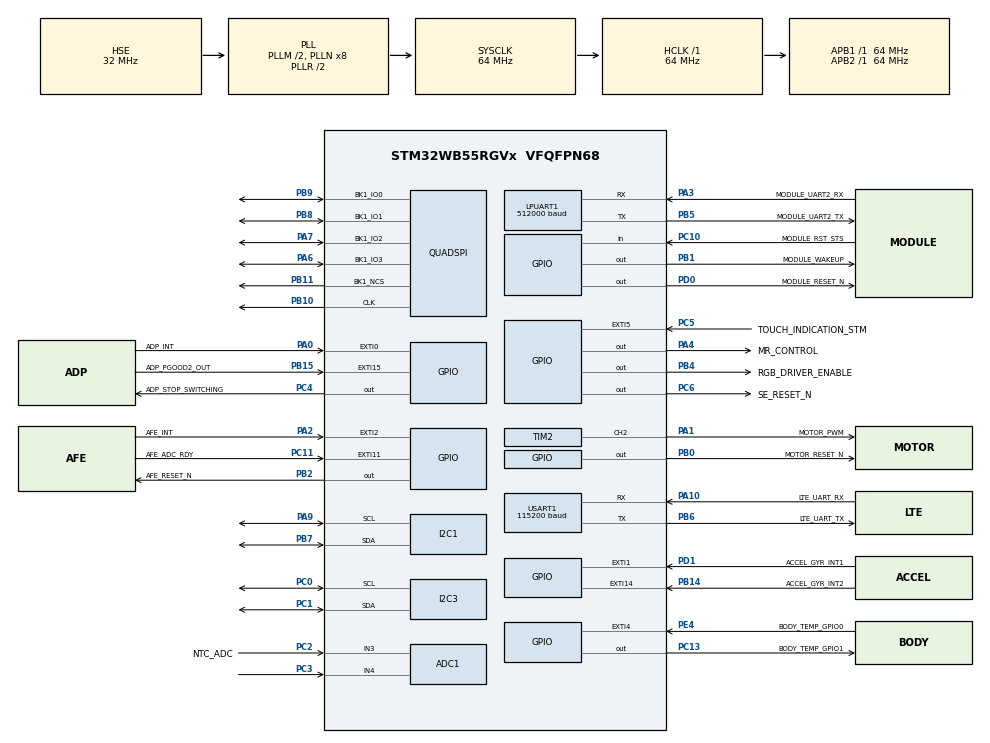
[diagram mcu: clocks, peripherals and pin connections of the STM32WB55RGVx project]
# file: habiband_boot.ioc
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ADC1.Channel-0\#ChannelRegularConversion=ADC_CHANNEL_3
ADC1.NbrOfConversionFlag=1
ADC1.OffsetNumber-0\#ChannelRegularConversion=ADC_OFFSET_NONE
ADC1.Rank-0\#ChannelRegularConversion=1
ADC1.SamplingTime-0\#ChannelRegularConversion=ADC_SAMPLETIME_2CYCLES_5
ADC1.master=1
I2C1.Timing=0x10707DBC
I2C3.Timing=0x10707DBC
LPUART1.BaudRate=512000
LPUART1.DMADisableonRxErrorParam=UART_ADVFEATURE_DMA_DISABLEONRXERROR
LPUART1.OverrunDisableParam=UART_ADVFEATURE_OVERRUN_DISABLE
Mcu.Family=STM32WB
Mcu.Name=STM32WB55RGVx
Mcu.Package=VFQFPN68
NVIC.EXTI15_10_IRQn=true\:0\:0\:false\:false\:true\:true\:true\:true
NVIC.EXTI1_IRQn=true\:0\:0\:false\:false\:true\:true\:true\:true
NVIC.EXTI4_IRQn=true\:0\:0\:false\:false\:true\:true\:true\:true
NVIC.EXTI9_5_IRQn=true\:0\:0\:false\:false\:true\:true\:true\:true
NVIC.HSEM_IRQn=true\:0\:0\:false\:false\:true\:false\:true\:true
NVIC.IPCC_C1_RX_IRQn=true\:0\:0\:false\:false\:true\:true\:true\:true
NVIC.IPCC_C1_TX_IRQn=true\:0\:0\:false\:false\:true\:true\:true\:true
NVIC.PriorityGroup=NVIC_PRIORITYGROUP_4
NVIC.RCC_IRQn=true\:0\:0\:false\:false\:true\:true\:false\:true
NVIC.RTC_WKUP_IRQn=true\:0\:0\:false\:false\:true\:true\:true\:true
NVIC.WWDG_IRQn=true\:0\:0\:false\:false\:true\:true\:true\:true
OSC_IN.Mode=HSE-External-Oscillator
OSC_IN.Signal=RCC_OSC_IN
OSC_OUT.Mode=HSE-External-Oscillator
OSC_OUT.Signal=RCC_OSC_OUT
PA0.GPIO_Label=ADP_INT
PA0.GPIO_ModeDefaultEXTI=GPIO_MODE_IT_FALLING
PA0.GPIO_PuPd=GPIO_PULLUP
PA0.Signal=GPXTI0
PA1.GPIO_Label=MOTOR_PWM
PA1.Signal=S_TIM2_CH2
PA10.GPIO_Label=LTE_UART_RX
PA10.Mode=Asynchronous
PA10.Signal=USART1_RX
PA11.GPIO_Label=LTE_UART_CTS
PA11.Signal=USART1_CTS
PA12.GPIO_Label=LTE_UART_RTS
PA12.Signal=USART1_RTS
PA13.Mode=Serial_Wire
PA13.Signal=SYS_JTMS-SWDIO
PA14.Mode=Serial_Wire
PA14.Signal=SYS_JTCK-SWCLK
PA15.Signal=SYS_JTDI
PA2.GPIO_Label=AFE_INT
PA2.Signal=GPXTI2
PA3.GPIO_Label=MODULE_UART2_RX
PA3.GPIO_Speed=GPIO_SPEED_FREQ_LOW
PA3.Mode=Asynchronous
PA3.Signal=LPUART1_RX
PA4.GPIO_Label=MR_CONTROL
PA4.GPIO_PuPd=GPIO_NOPULL
PA4.Signal=GPIO_Output
PA6.Mode=Single Bank 1
PA6.Signal=QUADSPI_BK1_IO3
PA7.Mode=Single Bank 1
PA7.Signal=QUADSPI_BK1_IO2
PA9.GPIO_Pu=GPIO_PULLUP
PA9.Mode=I2C
PA9.Signal=I2C1_SCL
PB0.GPIO_Label=MOTOR_RESET_N
PB0.Signal=GPIO_Output
PB1.GPIO_Label=MODULE_WAKEUP
PB1.Signal=GPIO_Output
PB10.Mode=Single Bank 1
PB10.Signal=QUADSPI_CLK
PB11.Mode=Single Bank 1
PB11.Signal=QUADSPI_BK1_NCS
PB12.GPIO_Label=MODULE_UART2_RTS
PB12.Signal=LPUART1_RTS
PB13.GPIO_Label=MODULE_UART2_CTS
PB13.Signal=LPUART1_CTS
PB14.GPIO_Label=ACCEL_GYR_INT2
PB14.Signal=GPXTI14
PB15.GPIO_Label=ADP_PGOOD2_OUT
PB15.Signal=GPXTI15
PB2.GPIO_Label=AFE_RESET_N
PB2.Signal=GPIO_Output
PB3.Signal=SYS_JTDO-SWO
PB4.GPIO_Label=RGB_DRIVER_ENABLE
PB4.GPIO_PuPd=GPIO_NOPULL
PB4.Signal=GPIO_Output
PB5.GPIO_Label=MODULE_UART2_TX
PB5.GPIO_Speed=GPIO_SPEED_FREQ_LOW
PB5.Mode=Asynchronous
PB5.Signal=LPUART1_TX
PB6.GPIO_Label=LTE_UART_TX
PB6.Mode=Asynchronous
PB6.Signal=USART1_TX
PB7.GPIO_Pu=GPIO_PULLUP
PB7.Mode=I2C
PB7.Signal=I2C1_SDA
PB8.Mode=Single Bank 1
PB8.Signal=QUADSPI_BK1_IO1
PB9.Mode=Single Bank 1
PB9.Signal=QUADSPI_BK1_IO0
PC0.GPIO_Pu=GPIO_PULLUP
PC0.Mode=I2C
PC0.Signal=I2C3_SCL
PC1.GPIO_Pu=GPIO_PULLUP
PC1.Mode=I2C
PC1.Signal=I2C3_SDA
PC10.GPIO_Label=MODULE_RST_STS
PC10.Signal=GPIO_Input
PC11.GPIO_Label=AFE_ADC_RDY
PC11.Signal=GPXTI11
PC12.GPIO_Label=STM_WAKEUP
PC12.Mode=SYS_WakeUp2
PC12.Signal=SYS_WKUP3
PC13.GPIO_Label=BODY_TEMP_GPIO1
PC13.Signal=GPIO_Output
PC14-OSC32_IN.Mode=LSE-External-Oscillator
PC14-OSC32_IN.Signal=RCC_OSC32_IN
PC15-OSC32_OUT.Mode=LSE-External-Oscillator
PC15-OSC32_OUT.Signal=RCC_OSC32_OUT
PC2.GPIO_Label=NTC_ADC
PC2.Signal=ADCx_IN3
PC3.Signal=ADCx_IN4
PC4.GPIO_Label=ADP_STOP_SWITCHING
PC4.Signal=GPIO_Output
PC5.GPIO_Label=TOUCH_INDICATION_STM
PC5.Signal=GPXTI5
PC6.GPIO_Label=SE_RESET_N
PC6.GPIO_PuPd=GPIO_NOPULL
PC6.Signal=GPIO_Output
PD0.GPIO_Label=MODULE_RESET_N
PD0.Signal=GPIO_Output
PD1.GPIO_Label=ACCEL_GYR_INT1
PD1.GPIO_ModeDefaultEXTI=GPIO_MODE_IT_RISING
PD1.GPIO_PuPd=GPIO_PULLDOWN
PD1.Signal=GPXTI1
PE4.GPIO_Label=BODY_TEMP_GPIO0
PE4.GPIO_ModeDefaultEXTI=GPIO_MODE_IT_RISING_FALLING
PE4.Signal=GPXTI4
ProjectManager.HeapSize=0x400
ProjectManager.StackSize=0x800
ProjectManager.TargetToolchain=STM32CubeIDE
RCC.ADCFreq_Value=48000000
RCC.AHB2CLKDivider=RCC_SYSCLK_DIV2
RCC.AHBFreq_Value=64000000
RCC.APB1Freq_Value=64000000
RCC.APB1TimFreq_Value=64000000
RCC.APB2Freq_Value=64000000
RCC.APB2TimFreq_Value=64000000
RCC.APB3Freq_Value=16000000
RCC.Cortex2_Div=SYSTICK_CLKSOURCE_HCLK_DIV8
RCC.CortexFreq_Value=64000000
RCC.HCLKFreq_Value=64000000
RCC.HSE_VALUE=32000000
RCC.HSI48_VALUE=48000000
RCC.HSI_VALUE=16000000
RCC.PLLM=RCC_PLLM_DIV2
RCC.PLLSAI1N=6
RCC.PLLSourceVirtual=RCC_PLLSOURCE_HSE
RCC.RFWKPClockSelection=RCC_RFWKPCLKSOURCE_LSE
RCC.RTCClockSelection=RCC_RTCCLKSOURCE_LSE
RCC.SYSCLKFreq_VALUE=64000000
RCC.SYSCLKSource=RCC_SYSCLKSOURCE_PLLCLK
RCC.USBFreq_Value=48000000
RCC.VCOOutputFreq_Value=128000000
RF1.Mode=RF1_Activate
RF1.Signal=RF_RF1
SH.ADCx_IN3.0=ADC1_IN3,IN3-Single-Ended
SH.ADCx_IN4.0=ADC1_IN4,IN4-Single-Ended
SH.S_TIM2_CH2.0=TIM2_CH2,PWM Generation2 CH2
STM32_WPAN.BT_SIG_BLOOD_PRESSURE_SENSOR=Disabled
STM32_WPAN.BT_SIG_HEALTH_THERMOMETER_SENSOR=Disabled
STM32_WPAN.BT_SIG_HEART_RATE_SENSOR=Disabled
STM32_WPAN.CFG_BLE_ATT_VALUE_ARRAY_SIZE=4096
STM32_WPAN.CFG_BLE_MAX_ATT_MTU=256
STM32_WPAN.CFG_BLE_NUM_GATT_SERVICES=10
STM32_WPAN.CFG_BLE_NUM_LINK=1
STM32_WPAN.CFG_GAP_DEVICE_NAME=habiband
STM32_WPAN.CUSTOM_P2P_SERVER=Disabled
STM32_WPAN.CUSTOM_TEMPLATE=Enabled
STM32_WPAN.INCLUDE_AD_TYPE_TX_POWER_LEVEL=1
STM32_WPAN.NUMBER_OF_SERVICES=1
STM32_WPAN.PAIRING_PARAMETERS=ON
STM32_WPAN.SERVICE1_CHAR1_LENGTH_CHARACTERISTIC=CHAR_VALUE_LEN_VARIABLE
STM32_WPAN.SERVICE1_CHAR1_LONG_NAME=BOOTLOADER_PORT_RX
STM32_WPAN.SERVICE1_CHAR1_PROP_WRITE=CHAR_PROP_WRITE
STM32_WPAN.SERVICE1_CHAR1_SHORT_NAME=BOOTLOADER_PORT_RX
STM32_WPAN.SERVICE1_CHAR1_UUID=B0 01
STM32_WPAN.SERVICE1_CHAR1_VALUE_LENGTH=200
STM32_WPAN.SERVICE1_CHAR2_LENGTH_CHARACTERISTIC=CHAR_VALUE_LEN_VARIABLE
STM32_WPAN.SERVICE1_CHAR2_LONG_NAME=BOOTLOADER_PORT_TX
STM32_WPAN.SERVICE1_CHAR2_PROP_NOTIFY=CHAR_PROP_NOTIFY
STM32_WPAN.SERVICE1_CHAR2_PROP_READ=CHAR_PROP_READ
STM32_WPAN.SERVICE1_CHAR2_SHORT_NAME=BOOTLOADER_PORT_TX
STM32_WPAN.SERVICE1_CHAR2_UUID=B0 02
STM32_WPAN.SERVICE1_CHAR2_VALUE_LENGTH=200
STM32_WPAN.SERVICE1_CHAR3_LENGTH_CHARACTERISTIC=CHAR_VALUE_LEN_VARIABLE
STM32_WPAN.SERVICE1_CHAR3_LONG_NAME=BOOTLOADER_STATUS
STM32_WPAN.SERVICE1_CHAR3_PROP_NOTIFY=CHAR_PROP_NOTIFY
STM32_WPAN.SERVICE1_CHAR3_PROP_READ=CHAR_PROP_READ
STM32_WPAN.SERVICE1_CHAR3_SHORT_NAME=BOOTLOADER_STATUS
STM32_WPAN.SERVICE1_CHAR3_UUID=B0 03
STM32_WPAN.SERVICE1_CHAR3_VALUE_LENGTH=20
STM32_WPAN.SERVICE1_CHAR4_LONG_NAME=BOOTLOADER_VERSION
STM32_WPAN.SERVICE1_CHAR4_PROP_READ=CHAR_PROP_READ
STM32_WPAN.SERVICE1_CHAR4_SHORT_NAME=BOOTLOADER_VERSION
STM32_WPAN.SERVICE1_CHAR4_UUID=B0 04
STM32_WPAN.SERVICE1_CHAR4_VALUE_LENGTH=20
STM32_WPAN.SERVICE1_LONG_NAME=SYSTEM_SERVICE
STM32_WPAN.SERVICE1_NUMBER_OF_CHARACTERISTICS=4
STM32_WPAN.SERVICE1_SHORT_NAME=SYSTEM_SERVICE
STM32_WPAN.SERVICE1_UUID=B0 00
STM32_WPAN.SERVICE2_CHAR1_LENGTH_CHARACTERISTIC=CHAR_VALUE_LEN_VARIABLE
STM32_WPAN.SERVICE2_CHAR1_LONG_NAME=ACCELEROMETER_POINTS
STM32_WPAN.SERVICE2_CHAR1_PROP_NOTIFY=CHAR_PROP_NOTIFY
STM32_WPAN.SERVICE2_CHAR1_PROP_READ=CHAR_PROP_READ
STM32_WPAN.SERVICE2_CHAR1_SHORT_NAME=ACCELEROMETER_POINTS
STM32_WPAN.SERVICE2_CHAR1_UUID=3C 01
STM32_WPAN.SERVICE2_CHAR1_VALUE_LENGTH=48
STM32_WPAN.SERVICE2_LONG_NAME=ACCELEROMETER_SERVICE
STM32_WPAN.SERVICE2_SHORT_NAME=ACCELEROMETER_SERVICE
STM32_WPAN.SERVICE2_UUID=3C 00
STM32_WPAN.SERVICE3_CHAR1_LONG_NAME=GYROSCOPE_POINTS
STM32_WPAN.SERVICE3_CHAR1_PROP_NOTIFY=CHAR_PROP_NOTIFY
STM32_WPAN.SERVICE3_CHAR1_PROP_READ=CHAR_PROP_READ
STM32_WPAN.SERVICE3_CHAR1_SHORT_NAME=GYROSCOPE_POINTS
STM32_WPAN.SERVICE3_CHAR1_UUID=4C 01
STM32_WPAN.SERVICE3_CHAR1_VALUE_LENGTH=48
STM32_WPAN.SERVICE3_LONG_NAME=GYROSCOPE_SERVICE
STM32_WPAN.SERVICE3_SHORT_NAME=GYROSCOPE_SERVICE
STM32_WPAN.SERVICE3_UUID=4C 00
STM32_WPAN.SERVICE4_CHAR1_LENGTH_CHARACTERISTIC=CHAR_VALUE_LEN_VARIABLE
STM32_WPAN.SERVICE4_CHAR1_LONG_NAME=ECG_POINTS
STM32_WPAN.SERVICE4_CHAR1_PROP_NOTIFY=CHAR_PROP_NOTIFY
STM32_WPAN.SERVICE4_CHAR1_PROP_READ=CHAR_PROP_READ
STM32_WPAN.SERVICE4_CHAR1_SHORT_NAME=ECG_POINTS
STM32_WPAN.SERVICE4_CHAR1_UUID=5C 01
STM32_WPAN.SERVICE4_CHAR1_VALUE_LENGTH=64
STM32_WPAN.SERVICE4_CHAR2_LENGTH_CHARACTERISTIC=CHAR_VALUE_LEN_VARIABLE
STM32_WPAN.SERVICE4_CHAR2_LONG_NAME=PPG_POINTS
STM32_WPAN.SERVICE4_CHAR2_PROP_NOTIFY=CHAR_PROP_NOTIFY
STM32_WPAN.SERVICE4_CHAR2_PROP_READ=CHAR_PROP_READ
STM32_WPAN.SERVICE4_CHAR2_SHORT_NAME=PPG_POINTS
STM32_WPAN.SERVICE4_CHAR2_UUID=5C 02
STM32_WPAN.SERVICE4_CHAR2_VALUE_LENGTH=64
STM32_WPAN.SERVICE4_CHAR3_LENGTH_CHARACTERISTIC=CHAR_VALUE_LEN_VARIABLE
STM32_WPAN.SERVICE4_CHAR3_LONG_NAME=ECG_MODE
STM32_WPAN.SERVICE4_CHAR3_SHORT_NAME=ECG_MODE
STM32_WPAN.SERVICE4_CHAR3_UUID=5C 03
STM32_WPAN.SERVICE4_CHAR3_VALUE_LENGTH=8
STM32_WPAN.SERVICE4_CHAR4_LENGTH_CHARACTERISTIC=CHAR_VALUE_LEN_VARIABLE
STM32_WPAN.SERVICE4_CHAR4_LONG_NAME=EKG_CMD
STM32_WPAN.SERVICE4_CHAR4_PROP_INDICATE=CHAR_PROP_INDICATE
STM32_WPAN.SERVICE4_CHAR4_PROP_WRITE=CHAR_PROP_WRITE
STM32_WPAN.SERVICE4_CHAR4_SHORT_NAME=EKG_CMD
STM32_WPAN.SERVICE4_CHAR4_UUID=5C 04
STM32_WPAN.SERVICE4_LONG_NAME=ECK_SERVICE
STM32_WPAN.SERVICE4_NUMBER_OF_CHARACTERISTICS=4
STM32_WPAN.SERVICE4_SHORT_NAME=ECK_SERVICE
STM32_WPAN.SERVICE4_UUID=5C 00
STM32_WPAN.SERVICE5_CHAR1_LENGTH_CHARACTERISTIC=CHAR_VALUE_LEN_VARIABLE
STM32_WPAN.SERVICE5_CHAR1_LONG_NAME=TerminalRequest
STM32_WPAN.SERVICE5_CHAR1_PROP_INDICATE=CHAR_PROP_INDICATE
STM32_WPAN.SERVICE5_CHAR1_PROP_WRITE=CHAR_PROP_WRITE
STM32_WPAN.SERVICE5_CHAR1_SHORT_NAME=TerminalRequest
STM32_WPAN.SERVICE5_CHAR1_UUID=E0 01
STM32_WPAN.SERVICE5_CHAR1_VALUE_LENGTH=40
STM32_WPAN.SERVICE5_CHAR2_LENGTH_CHARACTERISTIC=CHAR_VALUE_LEN_VARIABLE
STM32_WPAN.SERVICE5_CHAR2_LONG_NAME=TerminalResponse
STM32_WPAN.SERVICE5_CHAR2_PROP_NOTIFY=CHAR_PROP_NOTIFY
STM32_WPAN.SERVICE5_CHAR2_PROP_READ=CHAR_PROP_READ
STM32_WPAN.SERVICE5_CHAR2_SHORT_NAME=TerminalResponse
STM32_WPAN.SERVICE5_CHAR2_UUID=E0 02
STM32_WPAN.SERVICE5_CHAR2_VALUE_LENGTH=40
STM32_WPAN.SERVICE5_LONG_NAME=BOOTLOADER_SERVICE
STM32_WPAN.SERVICE5_NUMBER_OF_CHARACTERISTICS=2
STM32_WPAN.SERVICE5_SHORT_NAME=BOOTLOADER_SERVICE
STM32_WPAN.SERVICE5_UUID=E0 00
TIM2.Channel-PWM\ Generation2\ CH2=TIM_CHANNEL_2
USART1.BaudRate=115200
USART1.DMADisableonRxErrorParam=ADVFEATURE_DMA_DISABLEONRXERROR
USART1.OverrunDisableParam=ADVFEATURE_OVERRUN_DISABLE
USART1.VirtualMode-Asynchronous=VM_ASYNC
VP_CRC_VS_CRC.Mode=CRC_Activate
VP_HSEM_VS_HSEM.Mode=HSEM_Activate
VP_IPCC_VS_IPCC.Mode=IPCC_Activate
VP_RTC_VS_RTC_Activate.Mode=RTC_Enabled
VP_RTC_VS_RTC_WakeUp_intern.Mode=WakeUp
VP_SEQUENCER_VS_SEQUENCER.Mode=SEQUENCER_Enabled
VP_STM32_WPAN_VS_BLE_HOST.Mode=STM32_WPAN_Enabled
VP_TINY_LPM_VS_TINY_LPM.Mode=TINY_LPM_Enabled
VP_WWDG_VS_WWDG.Mode=WWDG_Activate
WWDG.EWIMode=WWDG_EWI_ENABLE
board=custom

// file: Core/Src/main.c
/* USER CODE BEGIN Header */
/**
  ******************************************************************************
  * @file           : main.c
  * @brief          : Main program body
  ******************************************************************************
  * @attention
  *
  * Copyright (c) 2022 STMicroelectronics.
  * All rights reserved.
  *
  * This software is licensed under terms that can be found in the LICENSE file
  * in the root directory of this software component.
  * If no LICENSE file comes with this software, it is provided AS-IS.
  *
  ******************************************************************************
  */
/* USER CODE END Header */
#include "main.h"
#include "adc.h"
#include "crc.h"
#include "i2c.h"
#include "ipcc.h"
#include "usart.h"
#include "quadspi.h"
#include "rf.h"
#include "rtc.h"
#include "tim.h"
#include "wwdg.h"
#include "gpio.h"

/* USER CODE BEGIN Includes */
#include "Components.h"
/* USER CODE END Includes */

void SystemClock_Config(void);
void PeriphCommonClock_Config(void);

/* USER CODE BEGIN 0 */
void dispose_system()
{
	HAL_IPCC_DeInit(&hipcc);
	HAL_DeInit();

}
/* USER CODE END 0 */

int main(void)
{
  /* USER CODE BEGIN 1 */
	HabibandBootloaderInit(main);
	HabibandBootloaderInitBootInput();
  /* USER CODE END 1 */

  /* MCU Configuration--------------------------------------------------------*/

  /* Reset of all peripherals, Initializes the Flash interface and the Systick. */
  HAL_Init();
  /* Config code for STM32_WPAN (HSE Tuning must be done before system clock configuration) */
  MX_APPE_Config();

  /* Configure the system clock */
  SystemClock_Config();

/* Configure the peripherals common clocks */
  PeriphCommonClock_Config();

  /* IPCC initialisation */
   MX_IPCC_Init();

  /* Initialize all configured peripherals */
  MX_GPIO_Init();
  MX_I2C3_Init();
  MX_I2C1_Init();
  MX_LPUART1_UART_Init();
  MX_USART1_UART_Init();
  MX_ADC1_Init();
  MX_QUADSPI_Init();
  MX_TIM2_Init();
  MX_CRC_Init();
  MX_RF_Init();
  MX_RTC_Init();
  //MX_WWDG_Init();
  /* USER CODE BEGIN 2 */
  ComponentsInit(main);
  /* USER CODE END 2 */

  /* Init code for STM32_WPAN */
  MX_APPE_Init();

  /* Infinite loop */
  /* USER CODE BEGIN WHILE */
  HabibandBootloaderInitSystemEnd();

  while (1)
  {
    /* USER CODE END WHILE */
    MX_APPE_Process();

    /* USER CODE BEGIN 3 */
    ComponentsHandler();

    //HAL_WWDG_Refresh(&hwwdg);
  }
  /* USER CODE END 3 */
}

void SystemClock_Config(void)
{
  RCC_OscInitTypeDef RCC_OscInitStruct = {0};
  RCC_ClkInitTypeDef RCC_ClkInitStruct = {0};

  /** Configure LSE Drive Capability
  */
  HAL_PWR_EnableBkUpAccess();
  __HAL_RCC_LSEDRIVE_CONFIG(RCC_LSEDRIVE_LOW);

  /** Configure the main internal regulator output voltage
  */
  __HAL_PWR_VOLTAGESCALING_CONFIG(PWR_REGULATOR_VOLTAGE_SCALE1);

  /** Initializes the RCC Oscillators according to the specified parameters
  * in the RCC_OscInitTypeDef structure.
  */
  RCC_OscInitStruct.OscillatorType = RCC_OSCILLATORTYPE_HSI|RCC_OSCILLATORTYPE_HSE
                              |RCC_OSCILLATORTYPE_LSE;
  RCC_OscInitStruct.HSEState = RCC_HSE_ON;
  RCC_OscInitStruct.LSEState = RCC_LSE_ON;
  RCC_OscInitStruct.HSIState = RCC_HSI_ON;
  RCC_OscInitStruct.HSICalibrationValue = RCC_HSICALIBRATION_DEFAULT;
  RCC_OscInitStruct.PLL.PLLState = RCC_PLL_ON;
  RCC_OscInitStruct.PLL.PLLSource = RCC_PLLSOURCE_HSE;
  RCC_OscInitStruct.PLL.PLLM = RCC_PLLM_DIV2;
  RCC_OscInitStruct.PLL.PLLN = 8;
  RCC_OscInitStruct.PLL.PLLP = RCC_PLLP_DIV2;
  RCC_OscInitStruct.PLL.PLLR = RCC_PLLR_DIV2;
  RCC_OscInitStruct.PLL.PLLQ = RCC_PLLQ_DIV2;
  if (HAL_RCC_OscConfig(&RCC_OscInitStruct) != HAL_OK)
  {
    Error_Handler();
  }

  /** Configure the SYSCLKSource, HCLK, PCLK1 and PCLK2 clocks dividers
  */
  RCC_ClkInitStruct.ClockType = RCC_CLOCKTYPE_HCLK4|RCC_CLOCKTYPE_HCLK2
                              |RCC_CLOCKTYPE_HCLK|RCC_CLOCKTYPE_SYSCLK
                              |RCC_CLOCKTYPE_PCLK1|RCC_CLOCKTYPE_PCLK2;
  RCC_ClkInitStruct.SYSCLKSource = RCC_SYSCLKSOURCE_PLLCLK;
  RCC_ClkInitStruct.AHBCLKDivider = RCC_SYSCLK_DIV1;
  RCC_ClkInitStruct.APB1CLKDivider = RCC_HCLK_DIV1;
  RCC_ClkInitStruct.APB2CLKDivider = RCC_HCLK_DIV1;
  RCC_ClkInitStruct.AHBCLK2Divider = RCC_SYSCLK_DIV2;
  RCC_ClkInitStruct.AHBCLK4Divider = RCC_SYSCLK_DIV1;

  if (HAL_RCC_ClockConfig(&RCC_ClkInitStruct, FLASH_LATENCY_3) != HAL_OK)
  {
    Error_Handler();
  }
}

void PeriphCommonClock_Config(void)
{
  RCC_PeriphCLKInitTypeDef PeriphClkInitStruct = {0};

  /** Initializes the peripherals clock
  */
  PeriphClkInitStruct.PeriphClockSelection = RCC_PERIPHCLK_SMPS|RCC_PERIPHCLK_RFWAKEUP;
  PeriphClkInitStruct.RFWakeUpClockSelection = RCC_RFWKPCLKSOURCE_LSE;
  PeriphClkInitStruct.SmpsClockSelection = RCC_SMPSCLKSOURCE_HSI;
  PeriphClkInitStruct.SmpsDivSelection = RCC_SMPSCLKDIV_RANGE1;

  if (HAL_RCCEx_PeriphCLKConfig(&PeriphClkInitStruct) != HAL_OK)
  {
    Error_Handler();
  }
}

void Error_Handler(void)
{
  __disable_irq();
  while (1)
  {
  }
}
